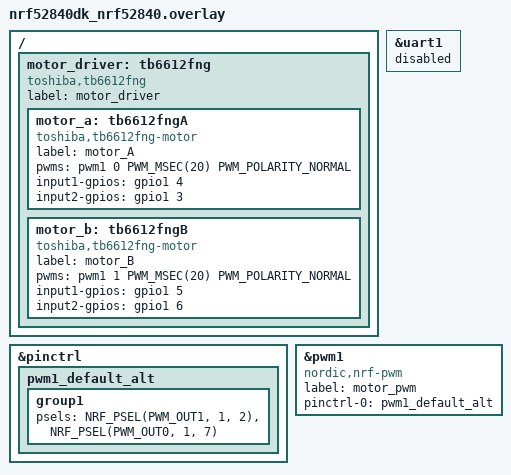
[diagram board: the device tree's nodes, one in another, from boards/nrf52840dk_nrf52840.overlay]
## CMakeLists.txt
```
#
# Copyright (c) 2019 Nordic Semiconductor
#
# SPDX-License-Identifier: LicenseRef-Nordic-5-Clause
#

cmake_minimum_required(VERSION 3.20.0)

find_package(Zephyr REQUIRED HINTS $ENV{ZEPHYR_BASE})
project(mesh_bot)

# Include application application event headers
zephyr_library_include_directories(src/events)

# NORDIC SDK APP START
target_sources(app PRIVATE 
    src/main.c
    src/model_handler.c
)

include_directories(
    src
    ../mesh_model_defines
)

add_subdirectory(src/modules)
add_subdirectory(src/events)
add_subdirectory(drivers)
# NORDIC SDK APP END
```

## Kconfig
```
#
# Copyright (c) 2021 Nordic Semiconductor ASA
#
# SPDX-License-Identifier: LicenseRef-Nordic-5-Clause
#

menu "Mesh robot"

config MESH_ROBOT_VERSION
	string "Mesh robot firmware version"
	default "0.0.0-development"

config MESH_ROBOT_VERSION_MAX_LEN
	int "Maximum length of the application firmware version"
	default 150

rsource "src/events/Kconfig"
rsource "src/modules/Kconfig"
rsource "drivers/tb6612fng/Kconfig"

endmenu

menu "Zephyr Kernel"
source "Kconfig.zephyr"
endmenu

module = APPLICATION_MODULE
module-str = Application module
source "subsys/logging/Kconfig.template.log_config"
```

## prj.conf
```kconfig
#
# Copyright (c) 2019 Nordic Semiconductor ASA
#
# SPDX-License-Identifier: LicenseRef-Nordic-5-Clause
#


# Logger configuration
CONFIG_LOG=y
CONFIG_LOG_DEFAULT_LEVEL=4
CONFIG_LOG_BACKEND_UART=y
CONFIG_MESH_MODULE_LOG_LEVEL_DBG=y
CONFIG_LOG_MESH_MODULE_EVENT=y
CONFIG_MOTOR_MODULE_LOG_LEVEL_DBG=y
CONFIG_LOG_MOTOR_MODULE_EVENT=y


# Configuration required by Application Event Manager
CONFIG_APP_EVENT_MANAGER=y
# CONFIG_HEAP_MEM_POOL_SIZE=2048
# CONFIG_REBOOT=y

# Memory
CONFIG_MAIN_STACK_SIZE=4096
CONFIG_HEAP_MEM_POOL_SIZE=2048

# NewLib C
CONFIG_NEWLIB_LIBC=y

CONFIG_DEBUG_OPTIMIZATIONS=y
CONFIG_DEBUG_THREAD_INFO=y

# PWM
CONFIG_PWM=y
CONFIG_GPIO=y

# Motors
CONFIG_TB6612FNG=y
CONFIG_TB6612FNG_MOTOR_DRIVER_LOG_LEVEL_DBG=y

CONFIG_SETTINGS=y
CONFIG_HWINFO=y

CONFIG_SYSTEM_WORKQUEUE_STACK_SIZE=2048
CONFIG_FLASH=y
CONFIG_FLASH_MAP=y
CONFIG_NVS=y
CONFIG_SETTINGS=y
CONFIG_HWINFO=y
CONFIG_DK_LIBRARY=y
CONFIG_PARTITION_MANAGER_ENABLED=y
CONFIG_PM_SINGLE_IMAGE=y
CONFIG_PM_PARTITION_SIZE_SETTINGS_STORAGE=0x8000

CONFIG_DK_LIBRARY=y

# Bluetooth
CONFIG_BT=y
CONFIG_BT_COMPANY_ID=0x0059
CONFIG_BT_DEVICE_NAME="Mesh bot"
CONFIG_BT_L2CAP_TX_MTU=69
CONFIG_BT_L2CAP_TX_BUF_COUNT=8
CONFIG_BT_OBSERVER=y
CONFIG_BT_PERIPHERAL=y
CONFIG_BT_SETTINGS=y
CONFIG_BT_RX_STACK_SIZE=4096

# Bluetooth mesh
CONFIG_BT_MESH=y
CONFIG_BT_MESH_RELAY=y
CONFIG_BT_MESH_FRIEND=y
CONFIG_BT_MESH_ADV_BUF_COUNT=13
CONFIG_BT_MESH_RX_SEG_MAX=10
CONFIG_BT_MESH_TX_SEG_MAX=10
CONFIG_BT_MESH_PB_GATT=y
CONFIG_BT_MESH_GATT_PROXY=y
CONFIG_BT_MESH_DK_PROV=y
CONFIG_BT_MESH_CFG_CLI=y
```

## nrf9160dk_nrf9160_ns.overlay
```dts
&pinctrl {
    pwm1_default_alt: pwm1_default_alt {
        group1 {
            psels = <NRF_PSEL(PWM_OUT0, 0, 6)>, <NRF_PSEL(PWM_OUT1, 0, 1)>;
            nordic,invert;
        };
    };
};

&pwm1 {
    compatible = "nordic,nrf-pwm";
    status = "okay";
    label = "motor_pwm";
    pinctrl-0 = <&pwm1_default_alt>;
    pinctrl-names = "default";
};

/{

    motor_driver: tb6612fng{
        compatible = "toshiba,tb6612fng";
        status = "okay";
        label = "motor_driver";

        motorA: tb6612fngA{
            compatible = "toshiba,tb6612fng-motor";
            status = "okay";
            label = "motorA";
            pwms = <&pwm1 0 PWM_MSEC(20) PWM_POLARITY_NORMAL>;
            input1-gpios = <&gpio0 4 0>;
            input2-gpios = <&gpio0 5 0>;
        };

        motorB: tb6612fngB{
            compatible = "toshiba,tb6612fng-motor";
            status = "okay";
            label = "motorB";
            pwms = <&pwm1 1 PWM_MSEC(20) PWM_POLARITY_NORMAL>;
            input1-gpios = <&gpio0 3 0>;
            input2-gpios = <&gpio0 2 0>;
        };
    };

};
```

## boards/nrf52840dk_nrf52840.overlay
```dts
&uart1 {
    status = "disabled";
};


&pinctrl {
    pwm1_default_alt: pwm1_default_alt {
        group1 {
            psels = <NRF_PSEL(PWM_OUT1, 1, 2)>, <NRF_PSEL(PWM_OUT0, 1, 7)>;
        };
    };
};

&pwm1 {
    compatible = "nordic,nrf-pwm";
    status = "okay";
    label = "motor_pwm";
    pinctrl-0 = <&pwm1_default_alt>;
    pinctrl-names = "default";
};

/{

    motor_driver: tb6612fng{
        compatible = "toshiba,tb6612fng";
        status = "okay";
        label = "motor_driver";

        motor_a: tb6612fngA{
            compatible = "toshiba,tb6612fng-motor";
            status = "okay";
            label = "motor_A";
            pwms = <&pwm1 0 PWM_MSEC(20) PWM_POLARITY_NORMAL>;
            input1-gpios = <&gpio1 4 0>;
            input2-gpios = <&gpio1 3 0>;
        };

        motor_b: tb6612fngB{
            compatible = "toshiba,tb6612fng-motor";
            status = "okay";
            label = "motor_B";
            pwms = <&pwm1 1 PWM_MSEC(20) PWM_POLARITY_NORMAL>;
            input1-gpios = <&gpio1 5 0>;
            input2-gpios = <&gpio1 6 0>;
        };

    };

};
```

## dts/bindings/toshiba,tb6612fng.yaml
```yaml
# Bindings for the toshiba tb6612fng dual brushed dc driver

compatible: "toshiba,tb6612fng"
description: "Dual brushed DC motor driver"

include: "base.yaml"

properties:
  standby-gpios: 
    type: phandle-array
    required: false

child-binding:
  compatible: "toshiba,tb6612fng-motor"
  description: Brushed DC Motor driven by tb6612fng

  include: "base.yaml"

  properties:
    pwms:
      type: phandle-array
      required: true
    
    input1-gpios:
      type: phandle-array
      required: false

    input2-gpios:
      type: phandle-array
      required: false
```

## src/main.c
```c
/*
 * Copyright (c) 2019 Nordic Semiconductor ASA
 *
 * SPDX-License-Identifier: LicenseRef-Nordic-5-Clause
 */

#include <app_event_manager.h>
#include <zephyr/logging/log.h>

#define MODULE main
#include "events/module_state_event.h"

#include <zephyr/logging/log.h>
LOG_MODULE_REGISTER(MODULE);

void main(void)
{
	if (app_event_manager_init()) {
		LOG_ERR("Application Event Manager not initialized");
	} else {
		module_set_state(MODULE_STATE_READY);
	}
}
```

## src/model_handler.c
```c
#include <zephyr/sys/byteorder.h>
#include <zephyr/bluetooth/mesh/msg.h>

#include "../../mesh_model_defines/robot_movement_srv.h"
#include "model_handler.h"

/* Application handler functions */
movement_received_handler_t app_movement_handler;
start_movement_handler_t app_start_movement_handler;

/* SIG models */

static struct bt_mesh_cfg_cli cfg_cli = {};

static void attention_on(struct bt_mesh_model *model)
{
    printk("attention_on()\n");
}

static void attention_off(struct bt_mesh_model *model)
{
    printk("attention_off()\n");
}

static const struct bt_mesh_health_srv_cb health_srv_cb = {
    .attn_on = attention_on,
    .attn_off = attention_off,
};

static struct bt_mesh_health_srv health_srv = {
    .cb = &health_srv_cb,
};

BT_MESH_HEALTH_PUB_DEFINE(health_pub, 0);

static struct bt_mesh_model sig_models[] = {
    BT_MESH_MODEL_CFG_SRV,
    BT_MESH_MODEL_CFG_CLI(&cfg_cli),
    BT_MESH_MODEL_HEALTH_SRV(&health_srv, &health_pub),
};

/* Vendor models */

static int movement_config_recieved(struct bt_mesh_model *model, struct bt_mesh_msg_ctx *ctx, struct net_buf_simple *buf)
{
    struct robot_movement_config *mov_conf = (struct robot_movement_config *)buf->data;
    int err = 0;
    if (app_movement_handler != NULL)
    {
        app_movement_handler(mov_conf);
    }
    return err;
}

static int start_movement_recieved(struct bt_mesh_model *model, struct bt_mesh_msg_ctx *ctx, struct net_buf_simple *buf)
{
    if (app_start_movement_handler != NULL){
        app_start_movement_handler();
    }
    return 0;
}

static const struct bt_mesh_model_op movement_server_ops[] = {
    {OP_VND_ROBOT_MOVEMENT_SET, BT_MESH_LEN_EXACT(sizeof(struct robot_movement_set_msg)), movement_config_recieved},
    {OP_VND_ROBOT_CLEAR_TO_MOVE, BT_MESH_LEN_EXACT(0), start_movement_recieved},
    BT_MESH_MODEL_OP_END,
};

static struct bt_mesh_model vendor_models[] = {
    BT_MESH_MODEL_VND(CONFIG_BT_COMPANY_ID, ROBOT_MOVEMENT_SRV_MODEL_ID, movement_server_ops, NULL, NULL),
};

/* Composition */
static struct bt_mesh_elem elements[] = {
    BT_MESH_ELEM(0, sig_models, vendor_models),
};

static struct bt_mesh_comp comp = {
    .cid = CONFIG_BT_COMPANY_ID,
    .elem = elements,
    .elem_count = ARRAY_SIZE(elements),
};

const struct bt_mesh_comp *model_handler_init(movement_received_handler_t movement_handler,
    start_movement_handler_t start_movement_handler)
{
    app_movement_handler = movement_handler;
    app_start_movement_handler = start_movement_handler;
    return &comp;
}
```

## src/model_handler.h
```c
#pragma once

#include <zephyr/bluetooth/mesh.h>
#include "../../mesh_model_defines/robot_movement_srv.h"

typedef void (*movement_received_handler_t)(struct robot_movement_set_msg *);
typedef void (*start_movement_handler_t)();

const struct bt_mesh_comp *model_handler_init(
    movement_received_handler_t movement_received_handler,
    start_movement_handler_t start_movement_handler);
```
